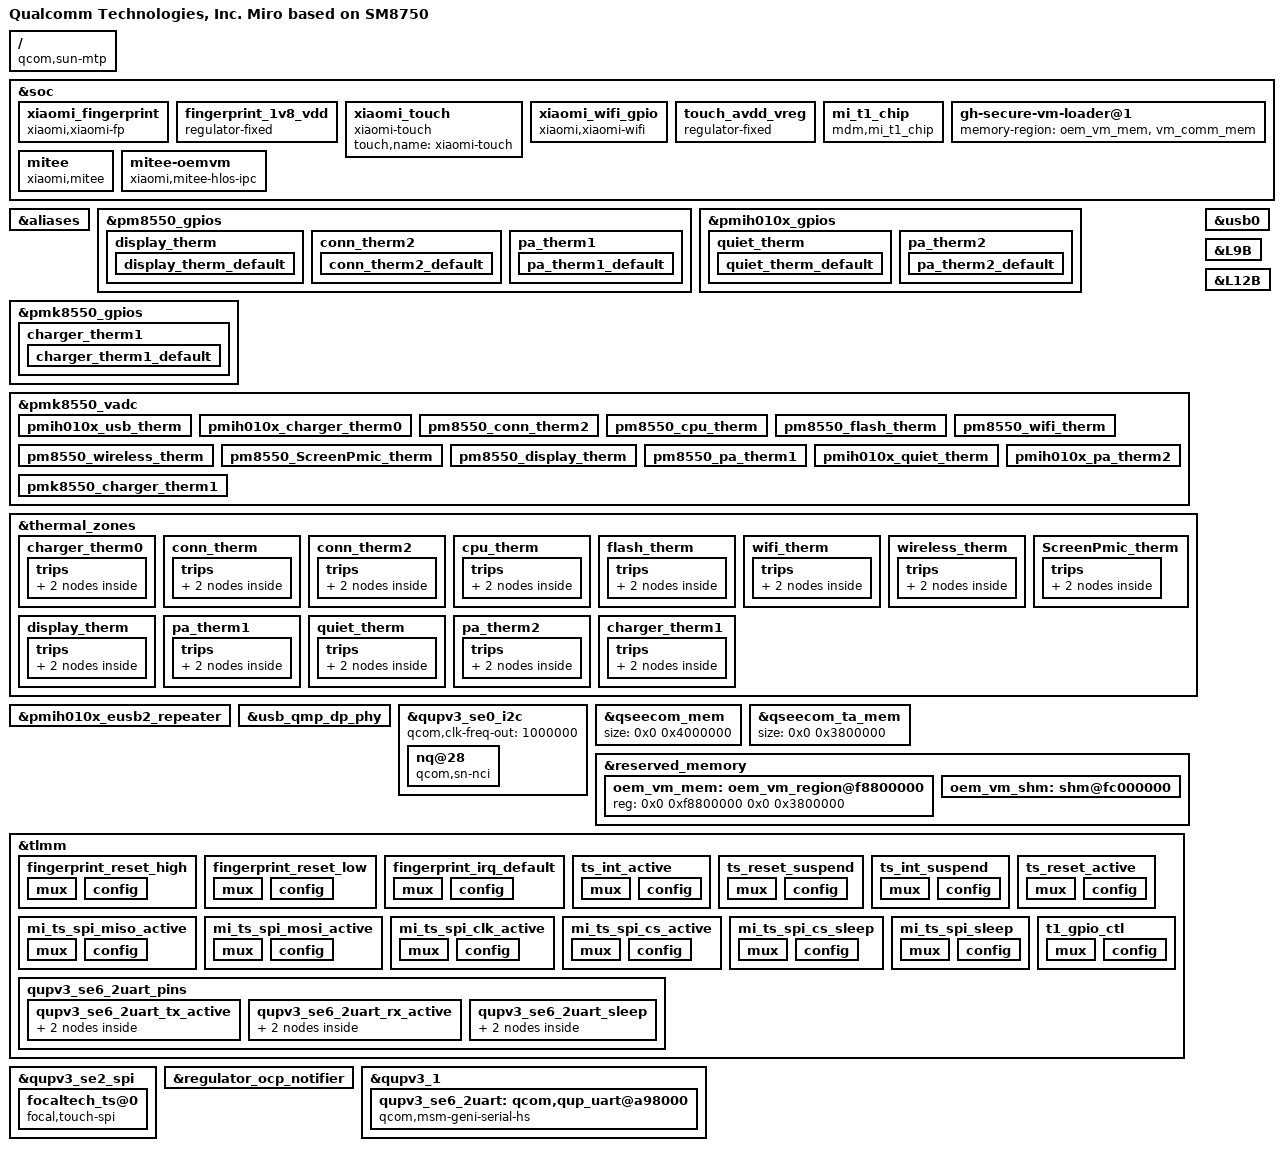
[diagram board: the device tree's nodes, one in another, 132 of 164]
/*
  this file is for attribution only of dada
  And public attribution of xiaomi platforms(like O2 O3)
*/


#include "sm8750-xiaomi-common.dtsi"
#include "miro-charger-common.dtsi"
#include "miro-nfc-pinctrl.dtsi"
#include "sm8750-ir-sensor-common.dtsi"
#include "miro-leds-common.dtsi"
#include <dt-bindings/clock/qcom,gcc-sun.h>
#include <dt-bindings/interrupt-controller/arm-gic.h>
#include <dt-bindings/interconnect/qcom,sun.h>
#include <dt-bindings/gpio/gpio.h>

/ {
	model = "Qualcomm Technologies, Inc. Miro based on SM8750";
	compatible = "qcom,sun-mtp", "qcom,sun", "qcom,sunp-mtp", "qcom,sunp",
			   "qcom,mtp";
	qcom,msm-id = <618 0x10000>, <618 0x20000>, <639 0x10000>, <639 0x20000>,
		      <0x100026a 0x10000>, <0x100026a 0x20000>,
		      <0x100027f 0x10000>, <0x100027f 0x20000>;
	qcom,board-id = <0x40008 0>;
	xiaomi,miboard-id = <0x3 0>;

};
/*statellite config */

&soc {
	xiaomi_fingerprint {
		compatible = "xiaomi,xiaomi-fp";
		xiaomi,gpio_irq = <&tlmm 85 0x0>;
		xiaomi,gpio_ipc = <&tlmm 85 0x0>;
		xiaomi,gpio_intr2 = <&tlmm 111 0x0>;
		xiaomi,vendor_names = "O11U_n2_431_131";
		fp_3v3_vreg-supply = <&L9B>;
		fp_1v8_vreg-supply = <&fingerprint_1v8_vdd>;
		netlink-event = <25>;
		sensor-loc = <606 2361 834 2589>;
		pinctrl-names = "reset_high", "reset_low","irq_default";
		pinctrl-0 = <&fingerprint_reset_high>;
		pinctrl-1 = <&fingerprint_reset_low>;
		pinctrl-2 = <&fingerprint_irq_default>;
		status = "ok";
	};

	fingerprint_1v8_vdd: fingerprint_1v8_vdd {
		compatible = "regulator-fixed";
		regulator-name = "fingerprint_1v8_vdd";
		regulator-min-microvolt = <1800000>;
		regulator-max-microvolt = <1800000>;
		gpio = <&tlmm 164 0x0>;
		enable-active-high;
	};

	xiaomi_touch {
		compatible = "xiaomi-touch";
		status = "ok";
		touch,name = "xiaomi-touch";
	};

	xiaomi_wifi_gpio {
		compatible = "xiaomi,xiaomi-wifi";
		gpio = <&tlmm 79 0x00>;
		debounce-time = <30>;
		pinctrl-names = "default";
		pinctrl-0 = <&wifi_ctrl_irq>;
		status = "ok";
	};

	touch_avdd_vreg: touch_avdd_vreg {
		compatible = "regulator-fixed";
		regulator-name = "touch_avdd_vreg";
		enable-active-high;
		gpio = <&tlmm 114 0>;
	};

	mi_t1_chip {
		compatible = "mdm,mi_t1_chip";
		gpio-count = <2>;
		first-gpio = <171>;
		mi-t1-gpio-1 = <&tlmm 171 0x0>;
		mi-t1-gpio-2 = <&tlmm 172 0x0>;
		pinctrl-0 = <&t1_gpio_ctl>;
	};
};

&aliases {
	spi0 = "/soc/qcom,qupv3_1_geni_se@ac0000/spi@a88000";
};

&pm8550_gpios {
	display_therm {
		display_therm_default: display_therm_default {
		pins = "gpio2";
		bias-high-impedance;
		};
    };
};

&pm8550_gpios {
	conn_therm2 {
		conn_therm2_default: conn_therm2_default {
		pins = "gpio4";
		bias-high-impedance;
		};
	};
};

&pm8550_gpios {
	pa_therm1 {
		pa_therm1_default: pa_therm1_default {
		pins = "gpio3";
		bias-high-impedance;
		};
	};
};

&pmih010x_gpios {
	quiet_therm {
		quiet_therm_default: quiet_therm_default {
		pins = "gpio6";
		bias-high-impedance;
		};
	};
};

&pmih010x_gpios {
	pa_therm2 {
		pa_therm2_default: pa_therm2_default {
		pins = "gpio18";
		bias-high-impedance;
		};
	};
};

&pmk8550_gpios {
	charger_therm1 {
		charger_therm1_default: charger_therm1_default {
		pins = "gpio2";
		bias-high-impedance;
		};
    };
};

&pmk8550_vadc {

	pinctrl-names = "default";
	pinctrl-0 =<&pa_therm1_default>,<&conn_therm2_default>,<&quiet_therm_default>,<&pa_therm2_default>,<&display_therm_default>,<&charger_therm1_default>;

	pmih010x_usb_therm {
		reg = <PMIH010X_ADC5_GEN4_AMUX_THM4_USB_THERM_100K_PU>;
		label = "pmih010x_usb_therm";
		qcom,ratiometric;
		qcom,hw-settle-time = <200>;
		qcom,pre-scaling = <1 1>;
		qcom,adc-tm-type = <1>;
		qcom,adc5-gen4;
	};

	pmih010x_charger_therm0 {
		reg = <PMIH010X_ADC5_GEN4_AMUX4_GPIO12_100K_PU>;
		label = "pmih010x_charger_therm0";
		qcom,ratiometric;
		qcom,pre-scaling = <1 1>;
		qcom,adc-tm-type = <1>;
		qcom,adc5-gen4;
	};

	pm8550_conn_therm2 {
		reg = <PM8550_ADC5_GEN3_AMUX2_GPIO4_100K_PU>;
		label = "pm8550_conn_therm2";
		qcom,ratiometric;
		qcom,pre-scaling = <1 1>;
		qcom,adc-tm-type = <1>;
	};

	pm8550_cpu_therm {
		reg = <PM8550_ADC5_GEN3_AMUX_THM1_100K_PU>;
		label = "pm8550_cpu_therm";
		qcom,ratiometric;
		qcom,hw-settle-time = <200>;
		qcom,pre-scaling = <1 1>;
		qcom,adc-tm-type = <1>;
	};

	pm8550_flash_therm {
		reg = <PM8550_ADC5_GEN3_AMUX_THM2_100K_PU>;
		label = "pm8550_flash_therm";
		qcom,ratiometric;
		qcom,hw-settle-time = <200>;
		qcom,pre-scaling = <1 1>;
		qcom,adc-tm-type = <1>;
	};

	pm8550_wifi_therm {
		reg = <PM8550_ADC5_GEN3_AMUX_THM3_100K_PU>;
		label = "pm8550_wifi_therm";
		qcom,ratiometric;
		qcom,hw-settle-time = <200>;
		qcom,pre-scaling = <1 1>;
		qcom,adc-tm-type = <1>;
	};

	pm8550_wireless_therm {
		reg = <PM8550_ADC5_GEN3_AMUX_THM4_100K_PU>;
		label = "pm8550_wireless_therm";
		qcom,ratiometric;
		qcom,hw-settle-time = <200>;
		qcom,pre-scaling = <1 1>;
		qcom,adc-tm-type = <1>;
	};

	pm8550_ScreenPmic_therm {
		reg = <PM8550_ADC5_GEN3_AMUX_THM5_100K_PU>;
		label = "pm8550_ScreenPmic_therm";
		qcom,ratiometric;
		qcom,hw-settle-time = <200>;
		qcom,pre-scaling = <1 1>;
		qcom,adc-tm-type = <1>;
	};

	pm8550_display_therm {
		reg = <PM8550_ADC5_GEN3_AMUX_THM6_GPIO2_100K_PU>;
		label = "pm8550_display_therm";
		qcom,ratiometric;
		qcom,pre-scaling = <1 1>;
		qcom,adc-tm-type = <1>;
	};

	pm8550_pa_therm1 {
		reg = <PM8550_ADC5_GEN3_AMUX1_GPIO3_100K_PU>;
		label = "pm8550_pa_therm1";
		qcom,ratiometric;
		qcom,pre-scaling = <1 1>;
		qcom,adc-tm-type = <1>;
	};

	pmih010x_quiet_therm {
		reg = <PMIH010X_ADC5_GEN4_AMUX1_GPIO6_100K_PU>;
		label = "pmih010x_quiet_therm";
		qcom,ratiometric;
		qcom,pre-scaling = <1 1>;
		qcom,adc-tm-type = <1>;
        qcom,adc5-gen4;
	};

	pmih010x_pa_therm2 {
		reg = <PMIH010X_ADC5_GEN4_AMUX5_GPIO18_100K_PU>;
		label = "pmih010x_pa_therm2";
		qcom,ratiometric;
		qcom,pre-scaling = <1 1>;
		qcom,adc-tm-type = <1>;
        qcom,adc5-gen4;
	};

	pmk8550_charger_therm1 {
		reg = <PMK8550_ADC5_GEN3_AMUX_THM3_GPIO2_100K_PU>;
		label = "pmk8550_charger_therm1";
		qcom,ratiometric;
		qcom,hw-settle-time = <200>;
		qcom,pre-scaling = <1 1>;
		qcom,adc-tm-type = <1>;
	};
};

&thermal_zones {
	charger_therm0 {
		polling-delay-passive = <0>;
		polling-delay = <0>;
		thermal-sensors = <&pmk8550_vadc PMIH010X_ADC5_GEN4_AMUX4_GPIO12_100K_PU>;
		trips {
			active-config0 {
				temperature = <125000>;
				hysteresis = <1000>;
				type = "passive";
			};

			active-config1 {
				temperature = <125000>;
				hysteresis = <1000>;
				type = "passive";
			};
		};
	};

	conn_therm {
		polling-delay-passive = <0>;
		polling-delay = <0>;
		thermal-sensors = <&pmk8550_vadc PMIH010X_ADC5_GEN4_AMUX_THM4_USB_THERM_100K_PU>;
		trips {
			active-config0 {
				temperature = <125000>;
				hysteresis = <1000>;
				type = "passive";
			};

			active-config1 {
				temperature = <125000>;
				hysteresis = <1000>;
				type = "passive";
			};
		};
	};

	conn_therm2 {
		polling-delay-passive = <0>;
		polling-delay = <0>;
		thermal-sensors = <&pmk8550_vadc PM8550_ADC5_GEN3_AMUX2_GPIO4_100K_PU>;
		trips {
			active-config0 {
				temperature = <125000>;
				hysteresis = <1000>;
				type = "passive";
			};

			active-config1 {
				temperature = <125000>;
				hysteresis = <1000>;
				type = "passive";
			};
		};
	};

	cpu_therm {
		polling-delay-passive = <0>;
		polling-delay = <0>;
		thermal-sensors = <&pmk8550_vadc PM8550_ADC5_GEN3_AMUX_THM1_100K_PU>;
		trips {
			active-config0 {
				temperature = <125000>;
				hysteresis = <1000>;
				type = "passive";
			};

			active-config1 {
				temperature = <125000>;
				hysteresis = <1000>;
				type = "passive";
			};
		};
	};

	flash_therm {
		polling-delay-passive = <0>;
		polling-delay = <0>;
		thermal-sensors = <&pmk8550_vadc PM8550_ADC5_GEN3_AMUX_THM2_100K_PU>;
		trips {
			active-config0 {
				temperature = <125000>;
				hysteresis = <1000>;
				type = "passive";
			};

			active-config1 {
				temperature = <125000>;
				hysteresis = <1000>;
				type = "passive";
			};
		};
	};

	wifi_therm {
		polling-delay-passive = <0>;
		polling-delay = <0>;
		thermal-sensors = <&pmk8550_vadc PM8550_ADC5_GEN3_AMUX_THM3_100K_PU>;
		trips {
			active-config0 {
				temperature = <125000>;
				hysteresis = <1000>;
				type = "passive";
			};

			active-config1 {
				temperature = <125000>;
				hysteresis = <1000>;
				type = "passive";
			};
		};
	};

	wireless_therm {
		polling-delay-passive = <0>;
		polling-delay = <0>;
		thermal-sensors = <&pmk8550_vadc PM8550_ADC5_GEN3_AMUX_THM4_100K_PU>;
		trips {
			active-config0 {
				temperature = <125000>;
				hysteresis = <1000>;
				type = "passive";
			};

			active-config1 {
				temperature = <125000>;
				hysteresis = <1000>;
				type = "passive";
			};
		};
	};

	ScreenPmic_therm {
		polling-delay-passive = <0>;
		polling-delay = <0>;
		thermal-sensors = <&pmk8550_vadc PM8550_ADC5_GEN3_AMUX_THM5_100K_PU>;
		trips {
			active-config0 {
				temperature = <125000>;
				hysteresis = <1000>;
				type = "passive";
			};

			active-config1 {
				temperature = <125000>;
				hysteresis = <1000>;
				type = "passive";
			};
		};
	};

	display_therm {
		polling-delay-passive = <0>;
		polling-delay = <0>;
		thermal-sensors = <&pmk8550_vadc PM8550_ADC5_GEN3_AMUX_THM6_GPIO2_100K_PU>;
		trips {
			active-config0 {
				temperature = <125000>;
				hysteresis = <1000>;
				type = "passive";
			};

			active-config1 {
				temperature = <125000>;
				hysteresis = <1000>;
				type = "passive";
			};
		};
	};

	pa_therm1 {
		polling-delay-passive = <0>;
		polling-delay = <0>;
		thermal-sensors = <&pmk8550_vadc PM8550_ADC5_GEN3_AMUX1_GPIO3_100K_PU>;
		trips {
			active-config0 {
				temperature = <125000>;
				hysteresis = <1000>;
				type = "passive";
			};

			active-config1 {
				temperature = <125000>;
				hysteresis = <1000>;
				type = "passive";
			};
		};
	};

	quiet_therm {
		polling-delay-passive = <0>;
		polling-delay = <0>;
		thermal-sensors = <&pmk8550_vadc PMIH010X_ADC5_GEN4_AMUX1_GPIO6_100K_PU>;
		trips {
			active-config0 {
				temperature = <125000>;
				hysteresis = <1000>;
				type = "passive";
			};

			active-config1 {
				temperature = <125000>;
				hysteresis = <1000>;
				type = "passive";
			};
		};
	};

	pa_therm2 {
		polling-delay-passive = <0>;
		polling-delay = <0>;
		thermal-sensors = <&pmk8550_vadc PMIH010X_ADC5_GEN4_AMUX5_GPIO18_100K_PU>;
		trips {
			active-config0 {
				temperature = <125000>;
				hysteresis = <1000>;
				type = "passive";
			};

			active-config1 {
				temperature = <125000>;
				hysteresis = <1000>;
				type = "passive";
			};
		};
	};

	charger_therm1 {
		polling-delay-passive = <0>;
		polling-delay = <0>;
		thermal-sensors = <&pmk8550_vadc PMK8550_ADC5_GEN3_AMUX_THM3_GPIO2_100K_PU>;
		trips {
			active-config0 {
				temperature = <125000>;
				hysteresis = <1000>;
				type = "passive";
			};

			active-config1 {
				temperature = <125000>;
				hysteresis = <1000>;
				type = "passive";
			};
		};
	};
};

&usb0 {
	qcom,wcd_usbss = <&wcd_usbss>;
	wcd_equ = <0xC0>;
};
&pmih010x_eusb2_repeater {
        qcom,host-param-override-seq =
                <0x00 0x50
                0x08 0x51
                0x03 0x52
                0x07 0x53
                0x02 0x54
                0x00 0x55
                0x03 0x56
                0x00 0x57
                0x02 0x58
                0x03 0x59
                0x01 0x5a
                0x02 0x5b>;
        qcom,param-override-seq =
                <0x00 0x50
                0x0b 0x51
                0x02 0x52
                0x07 0x53
                0x01 0x54
                0x03 0x55
                0x00 0x56
                0x06 0x57
                0x02 0x58
                0x03 0x59
                0x01 0x5a
                0x02 0x5b>;
};

&usb_qmp_dp_phy {
	usb3,eyegram-tuning;
	qcom,usb3-phy-eye-seq =
	/* <reg_offset, value>*/
		<USB3_DP_PCS_G12S1_TXMGN_V0 0x1F
			USB3_DP_PCS_G12S1_TXDEEMPH_M3P5DB 0x17>;
	qcom,host-usb3-phy-eye-seq =
		<USB3_DP_PCS_G12S1_TXMGN_V0 0x1F
			USB3_DP_PCS_G12S1_TXDEEMPH_M3P5DB 0x17>;
};

&qupv3_se0_i2c {
	status = "ok";
	qcom,clk-freq-out = <1000000>;
	#address-cells = <1>;
	#size-cells = <0>;
	nq@28 {
		compatible = "qcom,sn-nci";
		reg = <0x28>;
		qcom,sn-irq = <&tlmm 75 0x00>;
		qcom,sn-ven = <&tlmm 34 0x00>;
		qcom,sn-clkreq = <&tlmm 35 0x00>;
		qcom,sn-szone = "enable";
		interrupt-parent = <&tlmm>;
		interrupts = <75 0>;
		interrupt-names = "nfc_irq";
		pinctrl-names = "nfc_active", "nfc_suspend";
		pinctrl-0 = <&nfc_int_active &nfc_enable_active>;
		pinctrl-1 = <&nfc_int_suspend &nfc_enable_suspend>;
	};
};

&L9B {
	regulator-min-microvolt = <3300000>;
	regulator-max-microvolt = <3300000>;
	qcom,init-voltage = <3300000>;
};

&qseecom_mem {
		size = <0x0 0x4000000>;
};

&qseecom_ta_mem {
		size = <0x0 0x3800000>;
};

/* mitee vm */
&reserved_memory {
	oem_vm_mem: oem_vm_region@f8800000 {
		reg = <0x0 0xf8800000 0x0 0x3800000>;
	};

	oem_vm_shm: shm@fc000000 {
		no-map;
		reg = <0x0 0xfc000000 0x0 0x400000>;
		gunyah-label = <0x3>;
	};
};

&soc {
	gh-secure-vm-loader@1 {
		memory-region = <&oem_vm_mem &vm_comm_mem>;
	};

	mitee: mitee {
		compatible = "xiaomi,mitee";
		binding-core = <4 5 6>;
		tui-supported;
	};

	mitee-oemvm {
		compatible = "xiaomi,mitee-hlos-ipc";
		xiaomi,master;
		gunyah-shm-label = <0x3>;
		peer-name = <0x4>;
		shared-buffer = <&oem_vm_shm>;
	};
};
/* mitee vm */

/* begin touch */
&L12B {
	regulator-min-microvolt = <1800000>;
	regulator-max-microvolt = <1800000>;
	qcom,init-voltage = <1800000>;
};

&tlmm {
	/* FP_RESET_HIGH, state device active*/
	fingerprint_reset_high: fingerprint_reset_high {
		mux {
			pins = "gpio111";
			function = "gpio";
		};
		config {
			pins = "gpio111";
			drive-strength = <2>;
			bias-disable;
			output-high;
		};
	};
	/* FP_RESET_LOW */
	fingerprint_reset_low: fingerprint_reset_low {
		mux {
			pins = "gpio111";
			function = "gpio";
		};
		config {
			pins = "gpio111";
			drive-strength = <2>;
			bias-disable;
			output-low;
		};
	};
	/* FP_INT_N */
	fingerprint_irq_default: fingerprint_irq_default {
		mux {
			pins = "gpio85";
			function = "gpio";
		};
		config {
			pins = "gpio85";
			drive-strength = <2>;
			bias-pull-down;
		};
	};

	/* begin touch */
	ts_int_active: ts_int_active {
		mux {
			/* GPIO 162 Interrupt */
			pins = "gpio162";
			function = "gpio";
		};

		config {
			pins = "gpio162";
			drive-strength = <8>;
			bias-pull-up;
		};
	};

	ts_reset_suspend: ts_reset_suspend {
		mux {
			/* GPIO 161 Interrupt */
			pins = "gpio161";
			function = "gpio";
		};

		config {
			pins = "gpio161";
			drive-strength = <2>;
			bias-pull-down;
		};
	};

	ts_int_suspend: ts_int_suspend {
		mux {
			/* GPIO 162 Interrupt */
			pins = "gpio162";
			function = "gpio";
		};

		config {
			pins = "gpio162";
			drive-strength = <2>;
			bias-pull-down;
		};
	};

	ts_reset_active: ts_reset_active {
		mux {
			/* GPIO 161 Interrupt */
			pins = "gpio161";
			function = "gpio";
		};

		config {
			pins = "gpio161";
			drive-strength = <8>;
			bias-pull-up;
		};
	};

	mi_ts_spi_miso_active: mi_ts_spi_miso_active {
		mux {
			pins = "gpio40";
			function = "qup1_se2_l0";
		};
		config {
			pins = "gpio40";
			drive-strength = <6>;
			bias-disable;
		};
	};

	mi_ts_spi_mosi_active: mi_ts_spi_mosi_active {
		mux {
			pins = "gpio41";
			function = "qup1_se2_l1";
		};
		config {
			pins = "gpio41";
			drive-strength = <6>;
			bias-disable;
		};
	};

	mi_ts_spi_clk_active: mi_ts_spi_clk_active {
		mux {
			pins = "gpio42";
			function = "qup1_se2_l2";
		};
		config {
			pins = "gpio42";
			drive-strength = <6>;
			bias-disable;
		};
	};

	mi_ts_spi_cs_active: mi_ts_spi_cs_active {
		mux {
			pins = "gpio43";
			function = "qup1_se2_l3";
		};
		config {
			pins = "gpio43";
			drive-strength = <6>;
			bias-pull-up;
		};
	};


	mi_ts_spi_cs_sleep: mi_ts_spi_cs_sleep {
		mux {
			pins = "gpio43";
			function = "gpio";
		};
		config {
			pins = "gpio43";
			drive-strength = <6>;
			bias-disable;
		};
	};

	mi_ts_spi_sleep: mi_ts_spi_sleep {
		mux {
			pins = "gpio40", "gpio41",
				"gpio42";
			function = "gpio";
		};
		config {
			pins = "gpio40", "gpio41",
				"gpio42";
			drive-strength = <2>;
			bias-disable;
		};
	};
	/* end touch */

	t1_gpio_ctl: t1_gpio_ctl {
		mux {
			pins = "gpio171", "gpio172";
			function = "gpio";
		};
		config {
			pins = "gpio171", "gpio172";
			drive-strength = <2>;
			bias-disable;
			output-enable;
		};
	};
};

/* begin touch */
&qupv3_se2_spi {
	status = "ok";
	pinctrl-0 = <&mi_ts_spi_mosi_active>, <&mi_ts_spi_miso_active>,
				<&mi_ts_spi_clk_active>, <&mi_ts_spi_cs_active>;
	pinctrl-1 = <&mi_ts_spi_sleep>, <&mi_ts_spi_cs_sleep>;
	qcom,la-vm;
	qcom,rt;
	focaltech_ts@0 {
		compatible = "focal,touch-spi";
		reg = <0x0>;
		spi-max-frequency = <15000000>;
		interrupt-parent = <&tlmm>;
		interrupts = <162 0x2008>;
		focaltech,avdd-name = "avdd_focal";
		avdd-supply = <&touch_avdd_vreg>;
		focaltech,iovdd-name = "iovdd_focal";
		iovdd-supply = <&L12B>;
		focaltech,irq-gpio = <&tlmm 162 0x2008>;
		focaltech,reset-gpio = <&tlmm 161 0x00>;
		focaltech,max-touch-number = <10>;
		focaltech,super-resolution-factors = <100>;
		focaltech,display-coords =  <0 0 143999 319999>;
		focaltech,touch-range-array = <1 5 10 15 20>;
		focaltech,touch-def-array = <3 3 3 3>;
		focaltech,touch-expert-array = <10 10 10 10
						20 20 15 10
						20 20 20 10>;

		focaltech,support-fod = <1>;
		focaltech,fod-lx=<607>;
		focaltech,fod-ly=<2389>;
		focaltech,fod-x-size=<226>;
		focaltech,fod-y-size=<226>;
		focaltech,max-x = <1440>;
		focaltech,max-y = <3200>;
		focaltech,rx-num = <18>;
		focaltech,tx-num = <40>;
		focaltech,qts_en;
		focaltech,touch-type = "primary";
		qts,trusted-touch-mode = "vm_mode";
		qts,touch-environment = "tvm";
		qts,trusted-touch-type = "primary";
		qts,trusted-touch-spi-irq = <652>;
		qts,trusted-touch-io-bases = <0xa88000>;
		qts,trusted-touch-io-sizes = <0x1000>;
		qts,trusted-touch-vm-gpio-list = <&tlmm 40 0 &tlmm 41 0 &tlmm 42 0
                                          &tlmm 43 0 &tlmm 161 0 &tlmm 162 0x2008>;

		pinctrl-names = "pmx_ts_active", "pmx_ts_suspend";
		pinctrl-0 = <&ts_reset_active &ts_int_active>;
		pinctrl-1 = <&ts_int_suspend &ts_reset_suspend>;

		mi_tp,game-mode-array =
				<1 0 0 0 0>;  /* MAX MIN DEF SET GET	*/
		mi_tp,active-mode-array =
				<1 0 0 0 0>;  /* MAX MIN DEF SET GET	*/
		mi_tp,tolerance-array =
				<4 0 2 2 2>;  /* MAX MIN DEF SET GET	*/
		mi_tp,up-threshold-array =
				<4 0 3 3 3>;  /* MAX MIN DEF SET GET	*/
		mi_tp,aim-sensitivity-array =
				<4 0 2 2 2>;  /* MAX MIN DEF SET GET	*/
		mi_tp,tap-stability-array =
				<4 0 2 2 2>;  /* MAX MIN DEF SET GET	*/
		mi_tp,edge-filter-array =
				<3 0 2 2 2>;  /* MAX MIN DEF SET GET	*/
		mi_tp,panel-orien-array =
				<3 0 0 0 0>;  /* MAX MIN DEF SET GET	*/
		mi_tp,report-rate-array =
				<3 0 0 0 0>;  /* MAX MIN DEF SET GET	*/
		mi_tp,expert-mode-array =
				<3 1 1 1 1>;  /* MAX MIN DEF SET GET	*/
	};
};
/* end touch */

/*Remove PM8010 N for hardware design*/
&regulator_ocp_notifier {
	/delete-property/ periph-d40-supply;
	/delete-property/ periph-d41-supply;
	/delete-property/ periph-d42-supply;
	/delete-property/ periph-d43-supply;
	/delete-property/ periph-d44-supply;
	/delete-property/ periph-d45-supply;
	/delete-property/ periph-d46-supply;
};

/* Config uart for ASIC debug start */
&aliases {
	hsuart1 = &qupv3_se6_2uart;
};


&tlmm {
	qupv3_se6_2uart_pins: qupv3_se6_2uart_pins {
		qupv3_se6_2uart_tx_active: qupv3_se6_2uart_tx_active {
			mux {
				pins = "gpio58";
				function = "qup1_se6_l2";
			};

			config {
				pins = "gpio58";
				drive-strength = <2>;
				bias-disable;
			};
		};

		qupv3_se6_2uart_rx_active: qupv3_se6_2uart_rx_active {
			mux {
				pins = "gpio59";
				function = "qup1_se6_l3";
			};

			config {
				pins = "gpio59";
				drive-strength = <2>;
				bias-disable;
			};
		};

		qupv3_se6_2uart_sleep: qupv3_se6_2uart_sleep {
			mux {
				pins = "gpio58", "gpio59";
				function = "gpio";
			};

			config {
				pins = "gpio58", "gpio59";
				drive-strength = <2>;
				bias-pull-down;
			};
		};
	};
};

&qupv3_1 {
	qupv3_se6_2uart: qcom,qup_uart@a98000 {
		compatible = "qcom,msm-geni-serial-hs";
		reg = <0xa98000 0x4000>;
		reg-names = "se_phys";
		interrupts-extended = <&intc GIC_SPI 363 IRQ_TYPE_LEVEL_HIGH>,
				<&tlmm 59 IRQ_TYPE_LEVEL_HIGH>;
		clock-names = "se-clk";
		clocks = <&gcc GCC_QUPV3_WRAP1_S6_CLK>;
		interconnect-names = "qup-core", "qup-config", "qup-memory";
		interconnects =
		<&clk_virt MASTER_QUP_CORE_1 &clk_virt SLAVE_QUP_CORE_1>,
		<&gem_noc MASTER_APPSS_PROC &config_noc SLAVE_QUP_1>,
		<&aggre1_noc MASTER_QUP_1 &mc_virt  SLAVE_EBI1>;
		pinctrl-names = "default", "active", "sleep", "shutdown";
		pinctrl-0 = <&qupv3_se6_2uart_tx_active>, <&qupv3_se6_2uart_rx_active>;
		pinctrl-1 = <&qupv3_se6_2uart_tx_active>, <&qupv3_se6_2uart_rx_active>;
		pinctrl-2 = <&qupv3_se6_2uart_sleep>;
		pinctrl-3 = <&qupv3_se6_2uart_sleep>;
		qcom,auto-suspend-disable;
		status = "ok";
	};
};
/* Config uart for ASIC debug end */
